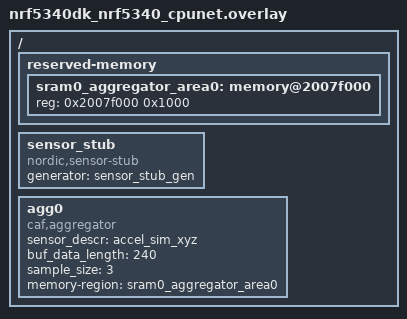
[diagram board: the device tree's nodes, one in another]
/*
 * Copyright (c) 2022 Nordic Semiconductor ASA
 *
 * SPDX-License-Identifier: LicenseRef-Nordic-5-Clause
 */

 / {

	reserved-memory {
		sram0_aggregator_area0: memory@2007f000 {
			reg = <0x2007f000 0x1000>;
		};
	};

	sensor_stub: sensor_stub {
		compatible = "nordic,sensor-stub";
		generator = "sensor_stub_gen";
		status = "okay";
	};

	agg0: agg0 {
		compatible = "caf,aggregator";
		sensor_descr = "accel_sim_xyz";
		buf_data_length = <240>;
		sample_size = <3>;
		memory-region = <&sram0_aggregator_area0>;
		status = "okay";
	};
};
